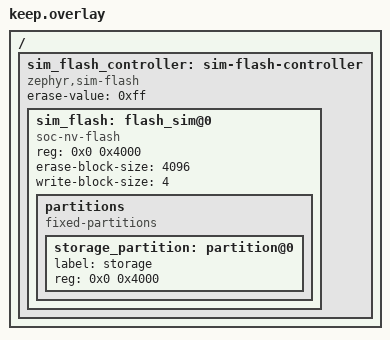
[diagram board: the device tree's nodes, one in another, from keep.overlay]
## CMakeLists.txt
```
# SPDX-FileCopyrightText: 2026 PHITES Embedded Research and Development on Engineering
# SPDX-License-Identifier: Apache-2.0

cmake_minimum_required(VERSION 3.20.0)
find_package(Zephyr REQUIRED HINTS $ENV{ZEPHYR_BASE})
project(tracegale_crash_test)

target_include_directories(app PRIVATE ${ZEPHYR_TRACEGALE_MODULE_DIR}/firmware/src)
target_sources(app PRIVATE src/fake.c)
target_sources_ifdef(CONFIG_TRACEGALE_CRASH_RAM app PRIVATE src/main.c)
target_sources_ifdef(CONFIG_TRACEGALE_CRASH_KEEP app PRIVATE src/keep.c)
# One of Zephyr's own coredump backends instead of Tracegale's store.
if(NOT CONFIG_TRACEGALE_CRASH_RAM)
  target_sources(app PRIVATE src/zephyr_backend.c)
endif()
```

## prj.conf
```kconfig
# SPDX-FileCopyrightText: 2026 PHITES Embedded Research and Development on Engineering
# SPDX-License-Identifier: Apache-2.0

CONFIG_ZTEST=y
CONFIG_TRACEGALE=y
CONFIG_TRACEGALE_TRANSPORT_CUSTOM=y
CONFIG_TRACEGALE_AUTOSTART=n
CONFIG_TEST_RANDOM_GENERATOR=y
CONFIG_ENTROPY_GENERATOR=y
# Small, so tests can fill it. The tests call the store directly, and don't crash.
CONFIG_TRACEGALE_CRASH_RAM_SIZE=512
CONFIG_TRACEGALE_CRASH_REBOOT=n
CONFIG_TRACEGALE_MAX_MESSAGE=256
# Upload hashes and builds messages on the test's own stack, as it would on Tracegale's thread.
CONFIG_ZTEST_STACK_SIZE=2048
# Each suite tests one feature. Reports of metrics have their own, in tests/metrics.
CONFIG_TRACEGALE_METRICS=n
# Logs have their own suite, in tests/logs.
CONFIG_TRACEGALE_LOGS=n
```

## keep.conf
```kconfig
# SPDX-FileCopyrightText: 2026 PHITES Embedded Research and Development on Engineering
# SPDX-License-Identifier: Apache-2.0

# Settings on NVS, as many applications have, on a simulated flash with 4 KB pages. This turns on
# CONFIG_TRACEGALE_CRASH_KEEP, which the tests in src/keep.c check.
CONFIG_FLASH=y
CONFIG_FLASH_MAP=y
CONFIG_NVS=y
CONFIG_SETTINGS=y
CONFIG_SETTINGS_NVS=y
```

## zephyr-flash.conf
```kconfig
# SPDX-FileCopyrightText: 2026 PHITES Embedded Research and Development on Engineering
# SPDX-License-Identifier: Apache-2.0

# Zephyr's flash partition backend instead of Tracegale's store, on a simulated flash. Choosing it turns
# CONFIG_TRACEGALE_CRASH_RAM off. The test is src/zephyr_backend.c.
CONFIG_FLASH=y
CONFIG_FLASH_MAP=y
CONFIG_DEBUG_COREDUMP_BACKEND_FLASH_PARTITION=y
```

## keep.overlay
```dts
/*
 * SPDX-FileCopyrightText: 2026 PHITES Embedded Research and Development on Engineering
 * SPDX-License-Identifier: Apache-2.0
 *
 * A simulated flash for settings, since the emulated boards have none that can be written.
 */

/ {
	sim_flash_controller: sim-flash-controller {
		compatible = "zephyr,sim-flash";
		#address-cells = <1>;
		#size-cells = <1>;
		erase-value = <0xff>;

		/* Zephyr v3.7's simulator finds its flash by this name. */
		sim_flash: flash_sim@0 {
			compatible = "soc-nv-flash";
			reg = <0x0 0x4000>;
			erase-block-size = <4096>;
			write-block-size = <4>;

			partitions {
				compatible = "fixed-partitions";
				#address-cells = <1>;
				#size-cells = <1>;

				storage_partition: partition@0 {
					label = "storage";
					reg = <0x0 0x4000>;
				};
			};
		};
	};
};
```

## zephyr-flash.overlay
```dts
/*
 * SPDX-FileCopyrightText: 2026 PHITES Embedded Research and Development on Engineering
 * SPDX-License-Identifier: Apache-2.0
 *
 * A simulated flash with the partition that Zephyr's flash coredump backend writes to.
 */

/ {
	sim_flash_controller: sim-flash-controller {
		compatible = "zephyr,sim-flash";
		#address-cells = <1>;
		#size-cells = <1>;
		erase-value = <0xff>;

		/* Zephyr v3.7's simulator finds its flash by this name. */
		sim_flash: flash_sim@0 {
			compatible = "soc-nv-flash";
			reg = <0x0 0x4000>;
			erase-block-size = <4096>;
			write-block-size = <4>;

			partitions {
				compatible = "fixed-partitions";
				#address-cells = <1>;
				#size-cells = <1>;

				coredump_partition: partition@0 {
					label = "coredump";
					reg = <0x0 0x4000>;
				};
			};
		};
	};
};
```

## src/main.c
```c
/*
 * SPDX-FileCopyrightText: 2026 PHITES Embedded Research and Development on Engineering
 * SPDX-License-Identifier: Apache-2.0
 *
 * The crash store and upload, fed the way Zephyr's coredump code feeds a backend, and sent to a fake server that follows
 * "Device to server" in docs/protocol/README.md.
 */

#include <errno.h>
#include <string.h>

#include <zephyr/debug/coredump.h>
#include <zephyr/kernel.h>
#include <zephyr/sys/byteorder.h>
#include <zephyr/ztest.h>

#include <tracegale/tracegale.h>

#include "build_id.h"
#include "crash.h"
#include "fake.h"
#include "sha256.h"
#include "transport.h"
#include "wire.h"

extern struct coredump_backend_api coredump_backend_other;

/* Builds a dump in Zephyr's format: a file header, then blocks. */
uint8_t dump[2048];
size_t dump_len;

void dump_begin(void)
{
	static const uint8_t header[12] = {'Z', 'E', 2, 0, 3, 0, 5, 0, 3, 0, 0, 0};

	memcpy(dump, header, sizeof(header));
	dump_len = sizeof(header);
}

void dump_block(char id, size_t len)
{
	dump[dump_len++] = id;
	sys_put_le16(2, &dump[dump_len]);
	sys_put_le16(len, &dump[dump_len + 2]);
	dump_len += 4;
	for (size_t i = 0; i < len; i++) {
		dump[dump_len++] = (uint8_t)(0xa0 + i);
	}
}

void dump_memory(uint32_t start, size_t len)
{
	dump[dump_len++] = 'M';
	sys_put_le16(1, &dump[dump_len]);
	sys_put_le32(start, &dump[dump_len + 2]);
	sys_put_le32(start + len, &dump[dump_len + 6]);
	dump_len += 10;
	for (size_t i = 0; i < len; i++) {
		dump[dump_len++] = (uint8_t)i;
	}
}

void feed(size_t piece)
{
	coredump_backend_other.start();
	for (size_t offset = 0; offset < dump_len; offset += piece) {
		coredump_backend_other.buffer_output(&dump[offset], MIN(piece, dump_len - offset));
	}
	coredump_backend_other.end();
}

size_t stored(uint8_t *out, size_t cap)
{
	int size = coredump_query(COREDUMP_QUERY_GET_STORED_DUMP_SIZE, NULL);
	struct coredump_cmd_copy_arg arg = {.offset = 0, .buffer = out, .length = MIN((size_t)size, cap)};

	if (size <= 0) {
		return 0;
	}
	zassert_equal(coredump_cmd(COREDUMP_CMD_COPY_STORED_DUMP, &arg), size);
	return size;
}

static void before(void *fixture)
{
	ARG_UNUSED(fixture);
	(void)coredump_cmd(COREDUMP_CMD_ERASE_STORED_DUMP, NULL);
#if defined(CONFIG_TRACEGALE_CRASH_KEEP)
	zassert_ok(tg_crash_kept_forget());
#endif
}

ZTEST(crash_store, test_small_dump_is_kept_whole)
{
	static uint8_t out[STORE_SIZE];
	uint8_t id[TG_BUILD_ID_MAX];
	const uint8_t *own;
	size_t own_len = tg_build_id(&own);

	zassert_equal(coredump_query(COREDUMP_QUERY_HAS_STORED_DUMP, NULL), 0);
	dump_begin();
	dump_block('A', 40);
	dump_memory(0x20001000, 100);
	feed(dump_len);
	zassert_equal(coredump_query(COREDUMP_QUERY_HAS_STORED_DUMP, NULL), 1);
	zassert_equal(coredump_cmd(COREDUMP_CMD_VERIFY_STORED_DUMP, NULL), 1);
	zassert_equal(stored(out, sizeof(out)), dump_len + MARK);
	zassert_mem_equal(out, dump, dump_len);
	zassert_equal(out[dump_len], 'M', "the mark is a memory block");
	zassert_equal(sys_get_le32(&out[dump_len + 7]) - sys_get_le32(&out[dump_len + 3]), 8);
	zassert_equal(tg_crash_stored_flags(), 0);
	zassert_equal(tg_crash_pending(), dump_len + MARK);

	zassert_true(own_len > 0, "the image has a build ID");
	zassert_equal(tg_crash_stored_build_id(id, sizeof(id)), own_len);
	zassert_mem_equal(id, own, own_len);
}

ZTEST(crash_store, test_identical_crashes_give_different_dumps)
{
	static uint8_t first[STORE_SIZE], second[STORE_SIZE];

	dump_begin();
	dump_block('A', 40);
	feed(dump_len);
	zassert_equal(stored(first, sizeof(first)), dump_len + MARK);
	feed(dump_len);
	zassert_equal(stored(second, sizeof(second)), dump_len + MARK);
	/* Otherwise the server would take the second for the first, resumed, and never count it. */
	zassert_true(memcmp(first, second, dump_len + MARK) != 0);
}

ZTEST(crash_store, test_pieces_of_any_size_give_the_same_dump)
{
	static uint8_t whole[STORE_SIZE], out[STORE_SIZE];
	size_t len;

	dump_begin();
	dump_block('A', 30);
	dump_block('T', 7);
	dump_memory(0x20000000, 64);
	dump_memory(0x20000400, 600);
	feed(dump_len);
	len = stored(whole, sizeof(whole));
	for (size_t piece = 1; piece < 20; piece++) {
		feed(piece);
		zassert_equal(stored(out, sizeof(out)), len, "piece size %u", (unsigned int)piece);
		/* Only the mark's contents differ. */
		zassert_mem_equal(out, whole, len - 8, "piece size %u", (unsigned int)piece);
	}
}

ZTEST(crash_store, test_large_memory_is_cut_at_its_end)
{
	static uint8_t out[STORE_SIZE];
	size_t len;
	size_t before_memory;

	dump_begin();
	dump_block('A', 40);
	before_memory = dump_len;
	dump_memory(0x20001000, 1000);
	/* Comes after a block that filled the store, so there's no room left for it. */
	dump_memory(0x20003000, 40);
	feed(7);
	len = stored(out, sizeof(out));
	zassert_true(len <= STORE_SIZE && len > STORE_SIZE - 14 - MARK, "used %u", (unsigned int)len);
	zassert_mem_equal(out, dump, before_memory + 6, "everything before the cut, and the start address, is unchanged");
	uint32_t start = sys_get_le32(&out[before_memory + 3]);
	uint32_t end = sys_get_le32(&out[before_memory + 7]);

	zassert_equal(start, 0x20001000);
	zassert_equal(end - start, len - MARK - before_memory - 11, "the block's end matches what was kept");
	zassert_equal((end - start) % 4, 0);
	zassert_mem_equal(&out[before_memory + 11], &dump[before_memory + 11], end - start);
	zassert_equal(tg_crash_stored_flags(), TG_CRASH_FLAG_CUT);
}

ZTEST(crash_store, test_register_block_too_large_is_left_out)
{
	static uint8_t out[STORE_SIZE];

	dump_begin();
	dump_block('A', STORE_SIZE);
	dump_memory(0x20001000, 64);
	feed(dump_len);
	zassert_equal(stored(out, sizeof(out)), 12 + 11 + 64 + MARK, "the header, the memory block and the mark");
	zassert_equal(out[12], 'M');
	zassert_equal(tg_crash_stored_flags(), TG_CRASH_FLAG_CUT);
}

ZTEST(crash_store, test_unknown_block_ends_the_dump)
{
	static uint8_t out[STORE_SIZE];
	size_t known;

	dump_begin();
	dump_block('A', 20);
	known = dump_len;
	dump_block('Q', 20);
	dump_memory(0x20001000, 64);
	feed(dump_len);
	zassert_equal(stored(out, sizeof(out)), known + MARK);
	zassert_equal(tg_crash_stored_flags(), TG_CRASH_FLAG_CUT);
}

ZTEST(crash_store, test_not_a_dump_is_not_kept)
{
	dump_begin();
	dump[0] = 'X';
	dump_block('A', 20);
	feed(dump_len);
	zassert_equal(coredump_query(COREDUMP_QUERY_HAS_STORED_DUMP, NULL), 0);

	dump_begin();
	dump[6] = 7; /* A pointer size of 128 bits. */
	dump_block('A', 20);
	feed(dump_len);
	zassert_equal(coredump_query(COREDUMP_QUERY_HAS_STORED_DUMP, NULL), 0);

	dump_begin();
	dump_len = 5;
	feed(dump_len);
	zassert_equal(coredump_query(COREDUMP_QUERY_HAS_STORED_DUMP, NULL), 0, "a header that never finished");
}

ZTEST(crash_store, test_changed_dump_is_refused)
{
	dump_begin();
	dump_block('A', 20);
	feed(dump_len);
	zassert_equal(coredump_query(COREDUMP_QUERY_HAS_STORED_DUMP, NULL), 1);
	tg_crash_ram_damage();
	zassert_equal(coredump_query(COREDUMP_QUERY_HAS_STORED_DUMP, NULL), 0, "the check found the damage");
	zassert_equal(tg_crash_pending(), 0);
}

ZTEST(crash_store, test_copy_and_erase)
{
	uint8_t out[64];
	struct coredump_cmd_copy_arg arg = {.offset = 20, .buffer = out, .length = sizeof(out)};

	dump_begin();
	dump_block('A', 20);
	feed(dump_len);
	zassert_equal(coredump_cmd(COREDUMP_CMD_COPY_STORED_DUMP, &arg), dump_len + MARK - 20, "only what is there");
	zassert_mem_equal(out, &dump[20], dump_len - 20);
	arg.offset = dump_len + MARK;
	zassert_equal(coredump_cmd(COREDUMP_CMD_COPY_STORED_DUMP, &arg), 0);
	arg.offset = -1;
	zassert_equal(coredump_cmd(COREDUMP_CMD_COPY_STORED_DUMP, &arg), -EINVAL);
	zassert_equal(coredump_cmd(COREDUMP_CMD_COPY_STORED_DUMP, NULL), -EINVAL);
	zassert_ok(coredump_cmd(COREDUMP_CMD_ERASE_STORED_DUMP, NULL));
	zassert_equal(coredump_query(COREDUMP_QUERY_HAS_STORED_DUMP, NULL), 0);
	arg.offset = 0;
	zassert_equal(coredump_cmd(COREDUMP_CMD_COPY_STORED_DUMP, &arg), -ENOENT);
}

ZTEST(crash_store, test_zephyr_writes_a_real_dump)
{
	static uint8_t out[STORE_SIZE];
	size_t len;

	/* Zephyr's own dump of this thread, without registers, since there was no fault. */
	coredump(K_ERR_KERNEL_OOPS, NULL, k_current_get());
	len = stored(out, sizeof(out));
	zassert_true(len > 12, "stored %u bytes", (unsigned int)len);
	zassert_equal(out[0], 'Z');
	zassert_equal(out[1], 'E');
	zassert_equal(sys_get_le32(&out[8]), K_ERR_KERNEL_OOPS);
	zassert_equal(out[12], 'M', "the thread's memory follows the header");
}

ZTEST_SUITE(crash_store, NULL, NULL, before, NULL, NULL);

void store_dump(void)
{
	dump_begin();
	dump_block('A', 40);
	dump_memory(0x20001000, 400);
	feed(dump_len);
	zassert_equal(tg_crash_pending(), dump_len + MARK);
}

void before_upload(void *fixture)
{
	before(fixture);
	fake_server_reset();
}

ZTEST(crash_upload, test_nothing_stored_sends_nothing)
{
	zassert_ok(send_crash());
	zassert_equal(srv.exchanges, 0);
}

ZTEST(crash_upload, test_sent_whole_then_erased)
{
	const uint8_t *own;
	size_t own_len = tg_build_id(&own);

	store_dump();
	zassert_ok(send_crash());
	zassert_true(srv.complete);
	zassert_equal(srv.have, dump_len + MARK);
	zassert_mem_equal(srv.data, dump, dump_len);
	zassert_equal(srv.chunks, DIV_ROUND_UP(dump_len + MARK, 100));
	zassert_equal(srv.build_id_len, own_len, "the build ID recorded with the crash is sent");
	zassert_mem_equal(srv.build_id, own, own_len);
	zassert_equal(tg_crash_pending(), 0, "erased once the server has it");
}

ZTEST(crash_upload, test_chunks_fit_the_device_buffer)
{
	store_dump();
	srv.chunk_max = 4096;
	zassert_ok(send_crash());
	zassert_true(srv.complete);
	zassert_equal(srv.chunks, DIV_ROUND_UP(dump_len + MARK, CONFIG_TRACEGALE_MAX_MESSAGE - 25));
}

ZTEST(crash_upload, test_dropped_connection_resumes)
{
	store_dump();
	srv.fail_exchange_at = 3;
	zassert_equal(send_crash(), -TRACEGALE_ERR_TIMEOUT);
	zassert_equal(tg_crash_pending(), dump_len + MARK, "kept until the server has all of it");
	zassert_equal(srv.have, 100);
	zassert_ok(send_crash());
	zassert_true(srv.complete);
	zassert_equal(srv.starts, 2);
	/* The chunk lost in the dropped exchange never reached the server, so nothing was sent twice. */
	zassert_equal(srv.bytes_received, dump_len + MARK);
	zassert_equal(tg_crash_pending(), 0);
}

ZTEST(crash_upload, test_lost_last_reply_finishes_without_resending)
{
	store_dump();
	/* START and five chunks: the server gets the last chunk, but its reply is lost. */
	srv.lose_reply_at = 1 + DIV_ROUND_UP(dump_len + MARK, 100);
	zassert_equal(send_crash(), -TRACEGALE_ERR_TIMEOUT);
	zassert_true(srv.complete);
	zassert_equal(tg_crash_pending(), dump_len + MARK, "the device doesn't know yet");
	srv.chunks = 0;
	zassert_ok(send_crash());
	zassert_equal(srv.chunks, 0, "the server says it's complete, so nothing is sent again");
	zassert_equal(tg_crash_pending(), 0);
}

ZTEST(crash_upload, test_identical_crash_is_sent_again)
{
	store_dump();
	zassert_ok(send_crash());
	feed(dump_len);
	srv.chunks = 0;
	zassert_ok(send_crash());
	zassert_true(srv.chunks > 0, "a second identical crash is a new upload");
	zassert_equal(tg_crash_pending(), 0);
}

ZTEST(crash_upload, test_hash_mismatch_gives_up_after_three)
{
	store_dump();
	srv.error_on_start = TG_WIRE_ERR_HASH_MISMATCH;
	zassert_equal(send_crash(), -1000 - TG_WIRE_ERR_HASH_MISMATCH);
	zassert_equal(send_crash(), -1000 - TG_WIRE_ERR_HASH_MISMATCH);
	zassert_equal(tg_crash_pending(), dump_len + MARK);
	zassert_equal(send_crash(), -1000 - TG_WIRE_ERR_HASH_MISMATCH);
	zassert_equal(tg_crash_pending(), 0);
}

ZTEST(crash_upload, test_refused_kind_is_erased)
{
	store_dump();
	srv.error_on_start = TG_WIRE_ERR_UNSUPPORTED_KIND;
	zassert_equal(send_crash(), -1000 - TG_WIRE_ERR_UNSUPPORTED_KIND);
	zassert_equal(tg_crash_pending(), 0, "this server will never take it");
}

ZTEST(crash_upload, test_busy_server_keeps_it)
{
	store_dump();
	srv.error_on_start = 12;
	zassert_equal(send_crash(), -1000 - 12);
	zassert_equal(tg_crash_pending(), dump_len + MARK);
}

ZTEST(crash_upload, test_forgotten_transfer_starts_again_once)
{
	store_dump();
	srv.forget_once = true;
	zassert_ok(send_crash());
	zassert_true(srv.complete);
	zassert_equal(srv.starts, 2);
	zassert_equal(tg_crash_pending(), 0);
}

ZTEST(crash_upload, test_stalled_server_is_a_bad_reply)
{
	store_dump();
	srv.stall = true;
	zassert_equal(send_crash(), -TRACEGALE_ERR_BAD_REPLY);
	zassert_true(srv.chunks <= 4, "gives up rather than send forever: %d", srv.chunks);
	zassert_equal(tg_crash_pending(), dump_len + MARK);
}

ZTEST(crash_upload, test_garbage_reply_keeps_it)
{
	store_dump();
	srv.garbage = true;
	zassert_equal(send_crash(), -TRACEGALE_ERR_BAD_REPLY);
	zassert_equal(tg_crash_pending(), dump_len + MARK);
}

ZTEST(crash_upload, test_zero_chunk_max_is_a_bad_reply)
{
	store_dump();
	srv.chunk_max = 0;
	zassert_equal(send_crash(), -TRACEGALE_ERR_BAD_REPLY);
	zassert_equal(tg_crash_pending(), dump_len + MARK);
}

ZTEST_SUITE(crash_upload, NULL, NULL, before_upload, NULL, NULL);
```

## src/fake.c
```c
/*
 * SPDX-FileCopyrightText: 2026 PHITES Embedded Research and Development on Engineering
 * SPDX-License-Identifier: Apache-2.0
 *
 * A fake server for the crash tests, following "Device to server" in docs/protocol/README.md. It's also the connection
 * Tracegale's core uses in these tests.
 */

#include <string.h>

#include <zephyr/kernel.h>
#include <zephyr/ztest.h>

#include <tracegale/tracegale.h>

#include "crash.h"
#include "fake.h"
#include "sha256.h"
#include "transport.h"
#include "wire.h"

struct fake_server srv;

static void reply_status(uint8_t *rx, size_t cap, size_t *rx_len, uint32_t id)
{
	struct tg_writer w;

	tg_write_begin(&w, rx, cap, TG_XFER_STATUS, id, 4);
	tg_write_uint(&w, 0, 7);
	tg_write_uint(&w, 1, srv.have);
	tg_write_uint(&w, 2, srv.chunk_max);
	tg_write_bool(&w, 3, srv.complete);
	*rx_len = w.len;
}

static void reply_error(uint8_t *rx, size_t cap, size_t *rx_len, uint32_t id, uint32_t code)
{
	struct tg_writer w;

	tg_write_begin(&w, rx, cap, TG_ERROR, id, 1);
	tg_write_uint(&w, 0, code);
	*rx_len = w.len;
}

static int fake_exchange(const uint8_t *tx, size_t tx_len, uint8_t *rx, size_t cap, size_t *rx_len, int *detail)
{
	struct tg_message m;
	const uint8_t *bytes;
	size_t len;
	uint32_t value;

	srv.exchanges++;
	if (srv.fail_exchange_at == srv.exchanges) {
		*detail = 113;
		return -TRACEGALE_ERR_TIMEOUT;
	}
	zassert_ok(tg_read_message(tx, tx_len, &m), "the device sent a message that breaks the specification");
	if (srv.garbage) {
		rx[0] = 0xff;
		*rx_len = 1;
		return 0;
	}
	if (m.type == TG_HELLO) {
		struct tg_writer w;

		tg_write_begin(&w, rx, cap, TG_ACK, m.id, 0);
		*rx_len = w.len;
		return 0;
	}
	if (m.type == TG_XFER_START) {
		srv.starts++;
		zassert_true(tg_read_uint(&m, 0, &value) && value == TG_XFER_KIND_COREDUMP);
		zassert_true(tg_read_uint(&m, 1, &value));
		zassert_true(tg_read_bytes(&m, 2, &bytes, &len) && len == TG_SHA256_SIZE);
		if (srv.error_on_start != 0) {
			reply_error(rx, cap, rx_len, m.id, srv.error_on_start);
			return 0;
		}
		if (srv.started && memcmp(bytes, srv.sha, len) != 0) {
			srv.started = false;
		}
		if (!srv.started) {
			srv.started = true;
			srv.complete = false;
			srv.have = 0;
			srv.total = value;
			memcpy(srv.sha, bytes, TG_SHA256_SIZE);
		}
		srv.build_id_len = 0;
		if (tg_read_bytes(&m, 3, &bytes, &len)) {
			srv.build_id_len = MIN(len, sizeof(srv.build_id));
			memcpy(srv.build_id, bytes, srv.build_id_len);
		}
		reply_status(rx, cap, rx_len, m.id);
		return 0;
	}
	zassert_equal(m.type, TG_XFER_CHUNK);
	srv.chunks++;
	zassert_true(tg_read_uint(&m, 0, &value) && value == 7);
	if (srv.forget_once) {
		srv.forget_once = false;
		srv.started = false;
		reply_error(rx, cap, rx_len, m.id, TG_WIRE_ERR_UNKNOWN_TRANSFER);
		return 0;
	}
	zassert_true(tg_read_uint(&m, 1, &value));
	zassert_true(tg_read_bytes(&m, 2, &bytes, &len));
	zassert_true(len <= srv.chunk_max, "a chunk larger than the server allows");
	srv.bytes_received += len;
	if (!srv.stall && value == srv.have && value + len <= srv.total) {
		memcpy(&srv.data[srv.have], bytes, len);
		srv.have += len;
		if (srv.have == srv.total) {
			uint8_t digest[TG_SHA256_SIZE];
			struct tg_sha256 ctx;

			tg_sha256_init(&ctx);
			tg_sha256_update(&ctx, srv.data, srv.have);
			tg_sha256_final(&ctx, digest);
			zassert_mem_equal(digest, srv.sha, sizeof(digest), "the device's SHA-256 matches its data");
			srv.complete = true;
			srv.completed++;
		}
	}
	reply_status(rx, cap, rx_len, m.id);
	if (srv.lose_reply_at == srv.exchanges) {
		*detail = 113;
		return -TRACEGALE_ERR_TIMEOUT;
	}
	return 0;
}

static int fake_open(int *detail)
{
	if (srv.offline) {
		*detail = 101;
		return -TRACEGALE_ERR_CONNECT;
	}
	return 0;
}

static void fake_close(void)
{
}

static const struct tg_transport fake = {.open = fake_open, .exchange = fake_exchange, .close = fake_close};

const struct tg_transport *tg_transport_get(void)
{
	return &fake;
}

static uint32_t ids;

static uint32_t next_id(void)
{
	return ++ids;
}

static uint8_t buffer[CONFIG_TRACEGALE_MAX_MESSAGE];

int send_crash(void)
{
	int detail = 0;
	int rc = tg_crash_send(&fake, buffer, sizeof(buffer), next_id, &detail);

	return rc == -TRACEGALE_ERR_SERVER ? -1000 - detail : rc;
}

void fake_server_reset(void)
{
	memset(&srv, 0, sizeof(srv));
	srv.chunk_max = 100;
}
```

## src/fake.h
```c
/*
 * SPDX-FileCopyrightText: 2026 PHITES Embedded Research and Development on Engineering
 * SPDX-License-Identifier: Apache-2.0
 *
 * What the crash tests share: a dump builder and a fake server, both in main.c.
 */

#ifndef TG_TEST_FAKE_H_
#define TG_TEST_FAKE_H_

#include <stdbool.h>
#include <stddef.h>
#include <stdint.h>

#include "build_id.h"
#include "sha256.h"

#if defined(CONFIG_TRACEGALE_CRASH_RAM)
#define STORE_SIZE CONFIG_TRACEGALE_CRASH_RAM_SIZE
#else
/* Room for a dump from one of Zephyr's own backends, which aren't limited to Tracegale's store. */
#define STORE_SIZE 8192
#endif
/* The memory block the store adds to every dump, holding its crash counter and cycle count. */
#define MARK (3 + 2 * sizeof(void *) + 8)

struct fake_server {
	uint8_t data[STORE_SIZE];
	size_t have;
	size_t total;
	uint8_t sha[TG_SHA256_SIZE];
	uint8_t build_id[TG_BUILD_ID_MAX];
	size_t build_id_len;
	bool started;
	bool complete;
	uint32_t chunk_max;
	int starts;
	int chunks;
	int bytes_received;
	int exchanges;
	/* Uploads the server got all of. */
	int completed;
	/* What to do wrong. */
	int fail_exchange_at;
	/* Handles the message, then loses the reply. */
	int lose_reply_at;
	uint32_t error_on_start;
	bool forget_once;
	bool stall;
	bool garbage;
	/* The device can't connect at all. */
	bool offline;
};

extern struct fake_server srv;

/* Starts the server again, with nothing received and nothing going wrong. */
void fake_server_reset(void);

/* Sends the stored crash to the server. @return 0, a negative tracegale_error, or -1000 minus the server's error code. */
int send_crash(void);

/* The rest is for Tracegale's own store, in main.c. */
extern uint8_t dump[2048];
extern size_t dump_len;

/* Build a dump in dump[]: the file header, a block of registers or thread data, and a block of memory. */
void dump_begin(void);
void dump_block(char id, size_t len);
void dump_memory(uint32_t start, size_t len);

/* Hands the dump to the store in pieces of this size, as Zephyr's coredump code would. */
void feed(size_t piece);

/* Copies the stored dump out. @return its size, or 0. */
size_t stored(uint8_t *out, size_t cap);

/* Stores a dump of a few hundred bytes. */
void store_dump(void);

/* Empties the store and the server. */
void before_upload(void *fixture);

/* Damages the store, as a fault in RAM or a power loss would. */
void tg_crash_ram_damage(void);

#endif /* TG_TEST_FAKE_H_ */
```

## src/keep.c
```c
/*
 * SPDX-FileCopyrightText: 2026 PHITES Embedded Research and Development on Engineering
 * SPDX-License-Identifier: Apache-2.0
 *
 * A crash kept through a power loss (CONFIG_TRACEGALE_CRASH_KEEP), on real settings storage: NVS on a simulated flash.
 * Whole attempts run through the core, against the fake server in main.c.
 *
 * A power loss is simulated the way the device sees one: the RAM store no longer holds a valid dump, and the boot-time
 * load runs again.
 */

#include <string.h>

#include <zephyr/debug/coredump.h>
#include <zephyr/kernel.h>
#include <zephyr/settings/settings.h>
#include <zephyr/ztest.h>

#include <tracegale/tracegale.h>

#include "core.h"
#include "crash.h"
#include "fake.h"
#include "store.h"
#include "wire.h"

#define KEPT_NAME "tracegale/crash"
/* What the store keeps before the dump: magic, checksum, length, flags and the build ID. */
#define KEPT_HEADER 48

static uint8_t kept[KEPT_HEADER + STORE_SIZE + 8];
static size_t kept_len;

static int read_kept(const char *key, size_t len, settings_read_cb read_cb, void *cb_arg, void *param)
{
	ARG_UNUSED(key);
	ARG_UNUSED(param);
	zassert_true(len <= sizeof(kept));
	zassert_equal(read_cb(cb_arg, kept, len), (ssize_t)len);
	kept_len = len;
	return 0;
}

/* Reads the copy in flash into kept[]. @return its size, or 0 when there's none. */
static size_t load_kept(void)
{
	kept_len = 0;
	zassert_ok(settings_load_subtree_direct(KEPT_NAME, read_kept, NULL));
	return kept_len;
}

static void power_loss(void)
{
	tg_crash_ram_damage();
	zassert_equal(tg_crash_pending(), 0, "RAM no longer holds a crash");
	tg_crash_kept_load();
}

static uint32_t crashes_sent(void)
{
	struct tracegale_status status;

	tracegale_get_status(&status);
	return status.crashes_sent;
}

static void *setup(void)
{
	/* Starts settings, as Tracegale's thread does at boot. */
	tg_store_load();
	return NULL;
}

ZTEST(crash_keep, test_crash_sent_at_once_never_touches_flash)
{
	store_dump();
	zassert_ok(tg_core_attempt());
	zassert_true(srv.complete);
	zassert_equal(tg_crash_pending(), 0);
	zassert_equal(load_kept(), 0, "a device that can report right away doesn't wear its flash");
}

ZTEST(crash_keep, test_unsent_crash_survives_power_loss)
{
	static uint8_t before[STORE_SIZE], after[STORE_SIZE];
	uint8_t id[TG_BUILD_ID_MAX], id_after[TG_BUILD_ID_MAX];
	size_t len, id_len;
	uint32_t sent = crashes_sent();

	store_dump();
	zassert_equal(load_kept(), 0, "nothing is kept before an attempt has failed");
	len = stored(before, sizeof(before));
	id_len = tg_crash_stored_build_id(id, sizeof(id));
	zassert_true(id_len > 0);

	srv.offline = true;
	zassert_equal(tg_core_attempt(), -TRACEGALE_ERR_CONNECT);
	zassert_equal(load_kept(), KEPT_HEADER + len, "kept once an attempt has failed");

	power_loss();
	zassert_equal(tg_crash_pending(), len, "the crash is back");
	zassert_equal(stored(after, sizeof(after)), len);
	zassert_mem_equal(after, before, len, "byte for byte, with its mark, so the server sees the same upload");
	zassert_equal(tg_crash_stored_build_id(id_after, sizeof(id_after)), id_len);
	zassert_mem_equal(id_after, id, id_len, "with the build ID recorded at the crash");

	srv.offline = false;
	zassert_ok(tg_core_attempt());
	zassert_true(srv.complete);
	zassert_mem_equal(srv.data, before, len);
	zassert_equal(crashes_sent(), sent + 1);
	zassert_equal(tg_crash_pending(), 0);
	zassert_equal(load_kept(), 0, "deleted from flash once the server has it");

	power_loss();
	zassert_equal(tg_crash_pending(), 0, "and it doesn't come back");
}

ZTEST(crash_keep, test_cut_flag_survives)
{
	/* A dump larger than the store. */
	dump_begin();
	dump_block('A', 40);
	dump_memory(0x20001000, 1000);
	feed(dump_len);
	zassert_equal(tg_crash_stored_flags(), TG_CRASH_FLAG_CUT);
	srv.offline = true;
	zassert_equal(tg_core_attempt(), -TRACEGALE_ERR_CONNECT);
	power_loss();
	zassert_true(tg_crash_pending() > 0);
	zassert_equal(tg_crash_stored_flags(), TG_CRASH_FLAG_CUT);
}

ZTEST(crash_keep, test_warm_restart_keeps_one_copy)
{
	size_t len;

	store_dump();
	len = tg_crash_pending();
	srv.offline = true;
	zassert_equal(tg_core_attempt(), -TRACEGALE_ERR_CONNECT);
	zassert_equal(load_kept(), KEPT_HEADER + len);

	/* A restart that kept RAM: the same crash is in RAM and in flash. */
	tg_crash_kept_load();
	zassert_equal(tg_crash_pending(), len);
	srv.offline = false;
	zassert_ok(tg_core_attempt());
	zassert_equal(srv.completed, 1, "sent once");
	zassert_equal(tg_crash_pending(), 0);
	zassert_equal(load_kept(), 0);
}

ZTEST(crash_keep, test_flash_keeps_the_first_crash_and_ram_the_newest)
{
	static uint8_t first[STORE_SIZE], second[STORE_SIZE];
	static uint8_t first_kept[sizeof(kept)];
	size_t len, kept_size;
	uint32_t sent = crashes_sent();

	store_dump();
	len = stored(first, sizeof(first));
	srv.offline = true;
	zassert_equal(tg_core_attempt(), -TRACEGALE_ERR_CONNECT);
	kept_size = load_kept();
	zassert_equal(kept_size, KEPT_HEADER + len);
	memcpy(first_kept, kept, kept_size);

	/* The device crashes again while offline: RAM now has the second crash. */
	feed(dump_len);
	zassert_equal(stored(second, sizeof(second)), len);
	zassert_true(memcmp(first, second, len) != 0);
	tg_crash_kept_load();
	zassert_equal(tg_core_attempt(), -TRACEGALE_ERR_CONNECT);
	zassert_equal(tg_core_attempt(), -TRACEGALE_ERR_CONNECT);
	zassert_equal(load_kept(), kept_size);
	zassert_mem_equal(kept, first_kept, kept_size, "the first crash stays: an offline crash loop writes flash once");

	/* Back online: the newest goes first, then the one from flash, in the same attempt. */
	srv.offline = false;
	zassert_ok(tg_core_attempt());
	zassert_equal(srv.completed, 2, "both crashes reached the server");
	zassert_mem_equal(srv.data, first, len, "the kept one went last");
	zassert_equal(crashes_sent(), sent + 2);
	zassert_equal(tg_crash_pending(), 0);
	zassert_equal(load_kept(), 0);
}

ZTEST(crash_keep, test_a_later_crash_is_kept_after_the_first_was_sent)
{
	size_t len;

	store_dump();
	srv.offline = true;
	zassert_equal(tg_core_attempt(), -TRACEGALE_ERR_CONNECT);
	srv.offline = false;
	zassert_ok(tg_core_attempt());
	zassert_equal(load_kept(), 0);

	feed(dump_len);
	len = tg_crash_pending();
	srv.offline = true;
	zassert_equal(tg_core_attempt(), -TRACEGALE_ERR_CONNECT);
	zassert_equal(load_kept(), KEPT_HEADER + len);
	power_loss();
	zassert_equal(tg_crash_pending(), len);
}

ZTEST(crash_keep, test_crash_given_up_is_deleted_from_flash)
{
	store_dump();
	srv.offline = true;
	zassert_equal(tg_core_attempt(), -TRACEGALE_ERR_CONNECT);
	zassert_true(load_kept() > 0);

	srv.offline = false;
	srv.error_on_start = TG_WIRE_ERR_UNSUPPORTED_KIND;
	zassert_equal(tg_core_attempt(), -TRACEGALE_ERR_SERVER);
	zassert_equal(tg_crash_pending(), 0, "this server will never take it");
	zassert_equal(load_kept(), 0, "so it must not come back after a power loss");
}

ZTEST(crash_keep, test_damaged_copy_is_never_loaded)
{
	size_t len;

	store_dump();
	srv.offline = true;
	zassert_equal(tg_core_attempt(), -TRACEGALE_ERR_CONNECT);
	len = load_kept();
	zassert_true(len > 0);

	/* One bit of the dump changed in flash. */
	kept[KEPT_HEADER + 20] ^= 0x10;
	zassert_ok(settings_save_one(KEPT_NAME, kept, len));
	power_loss();
	zassert_equal(tg_crash_pending(), 0, "the checksum found it");
	zassert_equal(load_kept(), 0, "and the bad copy is deleted");
}

ZTEST(crash_keep, test_copy_of_the_wrong_size_is_never_loaded)
{
	size_t len;

	store_dump();
	srv.offline = true;
	zassert_equal(tg_core_attempt(), -TRACEGALE_ERR_CONNECT);
	len = load_kept();
	(void)coredump_cmd(COREDUMP_CMD_ERASE_STORED_DUMP, NULL);

	/* Longer than this firmware's store, as after an update to a smaller CONFIG_TRACEGALE_CRASH_RAM_SIZE. */
	zassert_ok(settings_save_one(KEPT_NAME, kept, sizeof(kept)));
	tg_crash_kept_load();
	zassert_equal(tg_crash_pending(), 0);
	zassert_equal(load_kept(), 0);

	/* Its own length field says more than was saved. */
	zassert_ok(settings_save_one(KEPT_NAME, kept, len - 4));
	tg_crash_kept_load();
	zassert_equal(tg_crash_pending(), 0);
	zassert_equal(load_kept(), 0);

	/* Too short to be a dump. */
	zassert_ok(settings_save_one(KEPT_NAME, kept, 10));
	tg_crash_kept_load();
	zassert_equal(tg_crash_pending(), 0);
	zassert_equal(load_kept(), 0);
}

ZTEST(crash_keep, test_application_loading_settings_changes_nothing)
{
	size_t len;

	store_dump();
	len = tg_crash_pending();
	srv.offline = true;
	zassert_equal(tg_core_attempt(), -TRACEGALE_ERR_CONNECT);
	zassert_ok(settings_load(), "the kept crash isn't an error to the application's own load");
	zassert_equal(tg_crash_pending(), len);
	zassert_equal(load_kept(), KEPT_HEADER + len);
}

ZTEST(crash_keep, test_erasing_the_device_deletes_the_copy)
{
	store_dump();
	srv.offline = true;
	zassert_equal(tg_core_attempt(), -TRACEGALE_ERR_CONNECT);
	zassert_true(load_kept() > 0);
	zassert_ok(tracegale_provision_erase());
	zassert_equal(load_kept(), 0, "it holds the device's memory, so it goes with the credentials");
}

ZTEST_SUITE(crash_keep, NULL, setup, before_upload, NULL, NULL);
```

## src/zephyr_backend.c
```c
/*
 * SPDX-FileCopyrightText: 2026 PHITES Embedded Research and Development on Engineering
 * SPDX-License-Identifier: Apache-2.0
 *
 * Crash reports with one of Zephyr's own coredump backends, here the flash partition, instead of Tracegale's store. Tracegale
 * then only sends what that backend stored.
 */

#include <zephyr/debug/coredump.h>
#include <zephyr/kernel.h>
#include <zephyr/sys/byteorder.h>
#include <zephyr/ztest.h>

#include <tracegale/tracegale.h>

#include "build_id.h"
#include "core.h"
#include "crash.h"
#include "fake.h"

static void before(void *fixture)
{
	ARG_UNUSED(fixture);
	(void)coredump_cmd(COREDUMP_CMD_ERASE_STORED_DUMP, NULL);
	fake_server_reset();
	/* Zephyr's dump of a thread holds its whole stack, so it's larger than those from Tracegale's store. */
	srv.chunk_max = 4096;
}

ZTEST(crash_zephyr_backend, test_nothing_stored_sends_nothing)
{
	zassert_equal(tg_crash_pending(), 0);
	zassert_ok(tg_core_attempt());
	zassert_equal(srv.starts, 0);
}

ZTEST(crash_zephyr_backend, test_dump_from_zephyrs_backend_is_sent_then_erased)
{
	const uint8_t *own;
	size_t own_len = tg_build_id(&own);
	size_t size;

	/* Zephyr's own dump of this thread, written to the flash partition. */
	coredump(K_ERR_KERNEL_OOPS, NULL, k_current_get());
	size = tg_crash_pending();
	zassert_true(size > 12 && size <= sizeof(srv.data), "stored %u bytes", (unsigned int)size);

	srv.fail_exchange_at = 3;
	zassert_equal(tg_core_attempt(), -TRACEGALE_ERR_TIMEOUT);
	zassert_equal(tg_crash_pending(), size, "kept until the server has all of it");

	zassert_ok(tg_core_attempt());
	zassert_true(srv.complete);
	zassert_equal(srv.have, size);
	zassert_equal(srv.data[0], 'Z');
	zassert_equal(srv.data[1], 'E');
	zassert_equal(sys_get_le32(&srv.data[8]), K_ERR_KERNEL_OOPS);
	zassert_true(own_len > 0);
	zassert_equal(srv.build_id_len, own_len, "the running image's build ID, since this backend records none");
	zassert_mem_equal(srv.build_id, own, own_len);
	zassert_equal(tg_crash_pending(), 0, "erased once the server has it");
}

ZTEST_SUITE(crash_zephyr_backend, NULL, NULL, before, NULL, NULL);
```
